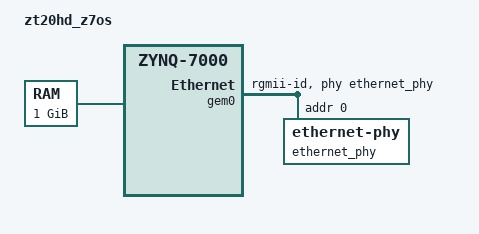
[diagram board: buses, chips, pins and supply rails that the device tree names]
/*
 * CAUTION: This file is automatically generated by PetaLinux SDK.
 * DO NOT modify this file
 */

/include/ "skeleton.dtsi"
/include/ "zynq-7000.dtsi"
/include/ "pcw.dtsi"
/include/ "pl.dtsi"

/ {
	model = "zt20hd_z7os";
	aliases {
		ethernet0 = &gem0;
		serial0 = &uart1;
		serial1 = &uart0;
	};
	chosen {
		bootargs = "console=ttyPS0,115200 earlyprintk hdmi devtmpfs.mount=1";
	};
	memory {
		device_type = "memory";
		reg = <0x0 0x40000000>;
	};
};

&gem0 {
	local-mac-address = [00 0a 35 00 1e 53];
	status = "okay";
	phy-mode = "rgmii-id";
	phy-handle = <&ethernet_phy>;

	ethernet_phy: ethernet-phy@0 {
		reg = <0x0>;
	};
};
